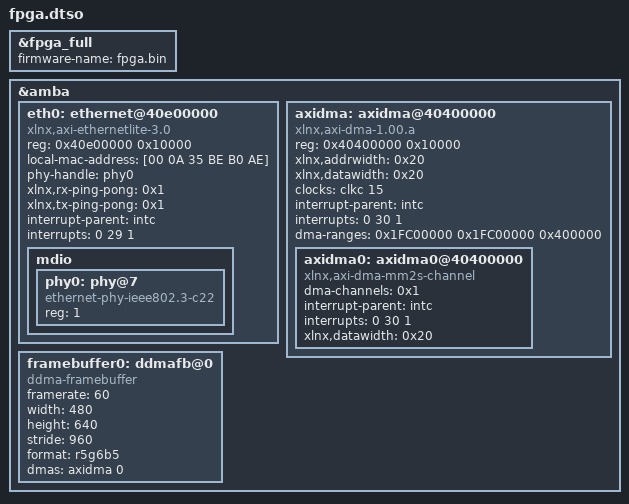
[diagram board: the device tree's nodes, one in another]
#include <dt-bindings/gpio/gpio.h>

/dts-v1/;
/plugin/;

/ {
	fragment@0 {
		target = <&fpga_full>;
		__overlay__ {
			status = "okay";
			firmware-name = "fpga.bin";
		};
	};

	fragment@1 {
		target = <&amba>;
		__overlay__ {
			eth0: ethernet@40e00000 {
				compatible = "xlnx,axi-ethernetlite-3.0", "xlnx,xps-ethernetlite-1.00.a";
				reg = <0x40e00000 0x10000>;
				status = "okay";
				device_type = "network";
				local-mac-address = [00 0A 35 BE B0 AE];
// Some random addresses to use for new boards:
//				local-mac-address = [00 0A 35 F3 D5 7D];
//				local-mac-address = [00 0A 35 BF 8D F9];
//				local-mac-address = [00 0A 35 03 23 B9];
//				local-mac-address = [00 0A 35 BB F5 EC];
//				local-mac-address = [00 0A 35 DC B1 11];
				phy-handle = <&phy0>;
			 	xlnx,rx-ping-pong = <0x1>;
				xlnx,tx-ping-pong = <0x1>;
				interrupt-parent = <&intc>;
		        interrupts = <0 29 1>;
				mdio {
					#address-cells = <1>;
					#size-cells = <0>;
					phy0: phy@7 {
						compatible = "ethernet-phy-ieee802.3-c22";
						device_type = "ethernet-phy";
						reg = <1>;
					};
				};
			};
		};
	};

	/* AXI DMA for driving displays */
	fragment@2 {
		target = <&amba>;
		__overlay__ {
			axidma: axidma@40400000 {
				compatible = "xlnx,axi-dma-1.00.a";
				reg = <0x40400000 0x10000>;
				xlnx,addrwidth = <0x20>;
				xlnx,datawidth = <0x20>;
				clocks = <&clkc 15>;
				clock-names = "s_axi_lite_aclk";
				interrupt-parent = <&intc>;
				interrupts = <0 30 1>;
				dma-ranges = <0x1FC00000 0x1FC00000 0x400000>;
				dma-names = "axidma0";
				#dma-cells = <1>;

				axidma0: axidma0@40400000 {
					compatible = "xlnx,axi-dma-mm2s-channel";
					dma-channels = <0x1>;
					interrupt-parent = <&intc>;
					interrupts = <0 30 1>;
					xlnx,datawidth = <0x20>;
					#dma-cells = <1>;
				};
			};
		};
	};

	/* Distributed DMA framebuffer driver */
	fragment@3 {
		target = <&amba>;
		__overlay__ {
			framebuffer0: ddmafb@0 {
				compatible = "ddma-framebuffer";
				status = "okay";
				framerate = <60>;
				width = <480>;
				height = <640>;
				stride = <960>;
				format = "r5g6b5";
				dmas = <&axidma 0>;
				dma-names = "axidma0";
			};
		};
	};
};
